# Template register map
Vendor: VendorName Co.Ltd; Series: SeriesName; File version: 1.2
CPU: CM7 r0p1, little endian, MPU, FPU, 4 interrupt priority bits
Registers are 32-bit, read-write, no defined reset value unless marked. A register's access mark holds for its fields unless they carry their own. Offsets are from the block's base; [hi:lo] are bit positions; {n}, {i} and the like mark numbered series; 'fields as' and 'values as' point back to an identical list.

## PMBUS — Power Management Bus
Base 0x40064000
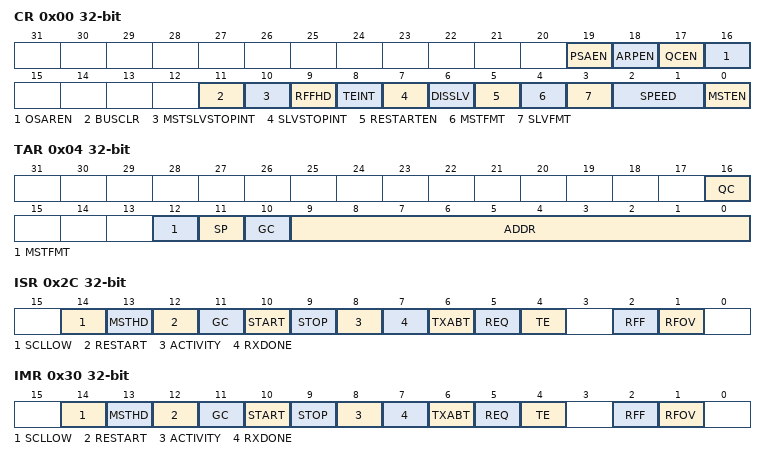
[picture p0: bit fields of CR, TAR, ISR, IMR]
0x00 CR — PMBUS control register
  [19] PSAEN — PMBUS PSAEN bit: enable PMBUS as persistent slave device
  [18] ARPEN — PMBUS ARPEN bit: ARP commands enable
  [17] QCEN — PMBUS QCEN bit: PMBUS slave receives quick commands enable
  [16] OSAREN — PMBUS OSAREN bit: enable the usage of OPT_SAR register
  [11] BUSCLR — PMBUS BUSCLR bit: bus clear is enabled
  [10] MSTSLVSTOPINT — PMBUS MSTSLVSTOPINT bit: master whether active
  [9] RFFHD ro — PMBUS RFFHD bit: PMBUS holds the bus selection
  [8] TEINT — PMBUS TEINT bit: controls whether a TX_EMPTY interrupt is generated
  [7] SLVSTOPINT — PMBUS SLVSTOPINT bit: controls whether a STOP interrupt is generated in the slave mode
  [6] DISSLV — PMBUS DISSLV bit: controls whether PMBUS has its slave disabled
  [5] RESTARTEN — PMBUS RESTARTEN bit: RESTART enable
  [4] MSTFMT ro — PMBUS MSTFMT bit: addressing mode when PMBUS is acting as a master
  [3] SLVFMT — PMBUS SLVFMT bit: controls whether it responds to 7- or 10-bit addresses
  [2:1] SPEED — PMBUS SPEED[1:0] bit: control at which speed the PMBUS operates in the master mode
  [0] MSTEN — PMBUS MSTEN bit: controls whether the PMBUS master is enabled
0x04 TAR — PMBUS target address register
  [16] QC — PMBUS QC bit: whether quick command is to be performed
  [12] MSTFMT — PMBUS MSTFMT bit: address transmit format selection
  [11] SP — PMBUS SP bit: whether software performs a general call or start byte command
  [10] GC — PMBUS GC bit: general call control
  [9:0] ADDR — PMBUS ADDR[9:0] bit: target address for any master transaction
0x08 SAR — PMBUS slave address register
  [9:0] ADDR — PMBUS ADDR[9:0] bit: PMBUS interface slave address
0x14 SSHR — PMBUS standard mode SCL high count register
  [15:0] PMBUS_SSHR — PMBUS PMBUS_SSHR[15:0] bit: set the SCL clock high-period count for standard mode
0x18 SSLR — PMBUS standard mode SCL low count register
  [15:0] PMBUS_SSLR — PMBUS PMBUS_SSLR[15:0] bit: set the SCL clock low-period count for standard mode
0x1C FSHR — PMBUS fast mode/fast mode plus SCL high count register
  [15:0] PMBUS_FSHR — PMBUS PMBUS_FSHR[15:0] bit: set the SCL clock high-period count for fast/fast plus mode
0x20 FSLR — PMBUS fast mode/fast mode plus SCL low count register
  [15:0] PMBUS_FSLR — PMBUS PMBUS_FSLR[15:0] bit: set the SCL clock low-period count for fast/fast plus mode
0x2C ISR ro — PMBUS interrupt status register
  [14] SCLLOW — PMBUS SCLLOW bit: SCL low power timeout detection
  [13] MSTHD — PMBUS MSTHD bit: master hold the bus
  [12] RESTART — PMBUS RESTART bit: restart detection
  [11] GC — PMBUS GC bit: general call
  [10] START — PMBUS START bit: START condition detection
  [9] STOP — PMBUS STOP bit: STOP condition detection
  [8] ACTIVITY — PMBUS ACTIVITY bit: capture PMBUS module activity
  [7] RXDONE — PMBUS RXDONE bit: slave transmit done
  [6] TXABT — PMBUS TXABT bit: transmit abort
  [5] REQ — PMBUS REQ bit: read request
  [4] TE — PMBUS TE bit: transmit buffer empty
  [2] RFF — PMBUS RFF bit: receive buffer full
  [1] RFOV — PMBUS RFOV bit: receive buffer overflow
0x30 IMR — PMBUS interrupt mask register
  [14] SCLLOW — PMBUS SCLLOW bit: SCL_STUCK_LOW interruption shield control
  [13] MSTHD — PMBUS MSTHD bit: MST_ON_HOLD interruption shield control
  [12] RESTART — PMBUS RESTART bit: RESTART interruption shield control
  [11] GC — PMBUS GC bit: GC interruption shield control
  [10] START — PMBUS START bit: START interruption shield control
  [9] STOP — PMBUS STOP bit: STOP interruption shield control
  [8] ACTIVITY — PMBUS ACTIVITY bit: ACTIVITY interruption shield control
  [7] RXDONE — PMBUS RXDONE bit: RX_DONE interruption shield control
  [6] TXABT — PMBUS TXABT bit: TX_ABRT interruption shield control
  [5] REQ — PMBUS REQ bit: RD_REQ interruption shield control
  [4] TE — PMBUS TE bit: TX_EMPTY interruption shield control
  [2] RFF — PMBUS RFF bit: RX_FULL interruption shield control
  [1] RFOV — PMBUS RFOV bit: RX_OVER interruption shield control
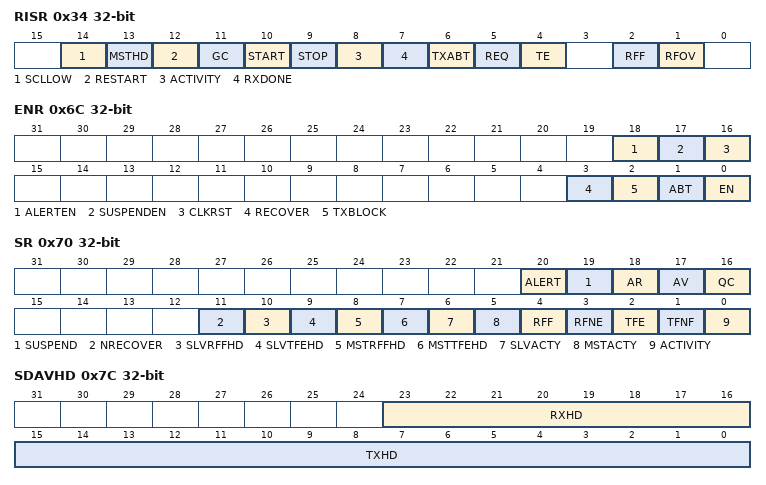
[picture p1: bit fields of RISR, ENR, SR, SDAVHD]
0x34 RISR ro — PMBUS RAW interrupt status register
  fields as ISR
0x38 RFTL — PMBUS receive threshold register
  [3:0] RX_TL — PMBUS RX_TL[3:0] bit: receive FIFO threshold level
0x3C TFTL — PMBUS transmit threshold register
  [3:0] TX_TL — PMBUS TX_TL[3:0] bit: transmit FIFO threshold level
0x40 ICR ro — PMBUS combined and independent interrupt clear register
  [0] ALL — PMBUS ALL bit: clear all combined and independent interrupts
0x48 CLRRXOV ro — PMBUS RX_OVER interrupt clear register
  [0] RFOV — PMBUS RFOV bit: clear the RX_OVER interrupt
0x50 CLRREQ ro — PMBUS RD_REQ interrupt clear register
  [0] RDREQ — PMBUS RDREQ bit: clear the RD_REQ interrupt
0x54 CLRTXABT ro — PMBUS TX_ABRT interrupt clear register
  [0] TXABT — PMBUS TXABT bit: clear the TX_ABRT interrupt
0x58 CLRRXDO ro — PMBUS RX_DONE interrupt clear register
  [0] RXDONE — PMBUS RXDONE bit: clear the RX_DONE interrupt
0x5C CLRACTY ro — PMBUS ACTIVITY interrupt clear register
  [0] ACTIVITY — PMBUS ACTIVITY bit: clears the ACTIVITY interrupt
0x60 CLRSTOP ro — PMBUS STOP_DET interrupt clear register
  [0] STOP — PMBUS STOP bit: clear the STOP interrupt
0x64 CLRSTART ro — PMBUS START_DET interrupt clear register
  [0] START — PMBUS START bit: clear the START interrupt
0x68 CLRGC ro — PMBUS GEN_CALL interrupt clear register
  [0] GC — PMBUS GC bit: clear the GC interrupt
0x6C ENR — PMBUS enable register
  [18] ALERTEN — PMBUS ALERTEN bit: PMBUS alert enable
  [17] SUSPENDEN — PMBUS SUSPENDEN bit: control PMBUS signal enable
  [16] CLKRST — PMBUS CLKRST bit: initiate the PMBUS master clock reset
  [3] RECOVER — PMBUS RECOVER bit: SDA recover mode enable
  [2] TXBLOCK — PMBUS TXBLOCK bit: block data transmit on PMBUS control
  [1] ABT — PMBUS ABT bit: PMBUS transfer abort
  [0] EN — PMBUS EN bit: PMBUS module enable
0x70 SR ro — PMBUS status register
  [20] ALERT — PMBUS ALERT bit: PMBUS alert status bit
  [19] SUSPEND — PMBUS SUSPEND bit: PMBUS stop signal status
  [18] AR — PMBUS AR bit: PMBUS save address resolved status bits
  [17] AV — PMBUS AV bit: PMBUS slave address valid status bit
  [16] QC — PMBUS QC bit: PMBUS quick command status bit
  [11] NRECOVER — PMBUS NRECOVER bit: an SDA stuck at low is not recovered after the recovery mechanism
  [10] SLVRFFHD — PMBUS SLVRFFHD bit: the BUS hold in slave mode due to the Rx FIFO being full
  [9] SLVTFEHD — PMBUS SLVTFEHD bit: the BUS hold in slave mode for the read request when the Tx FIFO is empty
  [8] MSTRFFHD — PMBUS MSTRFFHD bit: the BUS Hold in master mode due to Rx FIFO is Full
  [7] MSTTFEHD — PMBUS MSTTFEHD bit: the BUS hold because of the Tx FIFO being empty
  [6] SLVACTY — PMBUS SLVACTY bit: slave FSM activity status
  [5] MSTACTY — PMBUS MSTACTY bit: master FSM activity status
  [4] RFF — PMBUS RFF bit: receive FIFO completely full
  [3] RFNE — PMBUS RFNE bit: receive FIFO not empty
  [2] TFE — PMBUS TFE bit: transmit FIFO completely empty
  [1] TFNF — PMBUS TFNF bit: transmit FIFO not full
  [0] ACTIVITY — PMBUS ACTIVITY bit: PMBUS activity status
0x74 TFL ro — PMBUS transmit FIFO level register
  [4:0] TX_CNT — PMBUS TX_CNT[4:0] bit: contain the number of valid data entries in the transmit FIFO
0x78 RFL ro — PMBUS receive FIFO level register
  [4:0] RX_CNT — PMBUS RX_CNT[4:0] bit: contain the number of valid data entries in the transmit FIFO
0x7C SDAVHD — PMBUS SDA hold time register
  [23:16] RXHD — PMBUS RXHD[7:0] bit: set the internal SDA hold time
  [15:0] TXHD — PMBUS TXHD[15:0] bit: set the SDA hold time
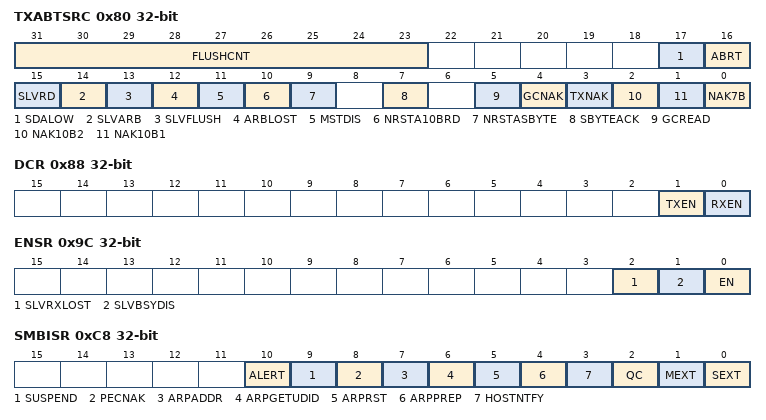
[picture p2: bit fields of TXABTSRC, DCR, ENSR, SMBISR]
0x80 TXABTSRC ro — PMBUS transfer abort source register
  [31:23] FLUSHCNT — PMBUS FLUSHCNT[8:0] bit: number of data/commands in the TX FIFO that were flushed due to transfer interrupt
  [17] SDALOW — PMBUS SDALOW bit: this bit is set when SDA low timeout is detected by the master device
  [16] ABRT — PMBUS ABRT bit: set when transfer abort is detected by the master device
  [15] SLVRD — PMBUS SLVRD bit: this bit is set when PMBUS is requested for data from send mode to write 1 to PMBUS_DR.CMD
  [14] SLVARB — PMBUS SLVARB bit: this bit and bit 12 are set simultaneously if the bus is lost when the slave device sends data
  [13] SLVFLUSH — PMBUS SLVFLUSH bit: clear TX FIFO old data
  [12] ARBLOST — PMBUS ARBLOST bit: this bit is set if the master device arbitration fails
  [11] MSTDIS — PMBUS MSTDIS bit: this bit is set when the master device is operated in the disabled master mode
  [10] NRSTA10BRD — PMBUS NRSTA10BRD bit: the master device sends a read request in 10-bit addressing mode
  [9] NRSTASBYTE — PMBUS NRSTASBYTE bit: send the start byte when RESTART is not enabled
  [7] SBYTEACK — PMBUS SBYTEACK bit: set when the master device sends the start byte and is responded
  [5] GCREAD — PMBUS GCREAD bit: set when the master device sends a general call
  [4] GCNAK — PMBUS GCNAK bit: set when no slave device responds after a general call is sent by the master device
  [3] TXNAK — PMBUS TXNAK bit: no slave device responds to the data sent
  [2] NAK10B2 — PMBUS NAK10B2 bit: the master device operates in 10-bit addressing mode
  [1] NAK10B1 — PMBUS NAK10B1 bit: the master device operates in 10-bit addressing mode
  [0] NAK7B — PMBUS NAK7B bit: the master device operates in 7-bit addressing mode
0x84 SLVNAK — PMBUS slave receive NACK register
  [0] NACK — PMBUS NACK bit: generate NACK control
0x88 DCR — PMBUS DMA control register
  [1] TXEN — PMBUS TXEN bit: transmit DMA enable
  [0] RXEN — PMBUS RXEN bit: receive DMA enable
0x8C DTTL — PMBUS DMA transmit waterline register
  [3:0] DMATDL — PMBUS DMATDL[3:0] bit: DMA transmit data level
0x90 DRTL — PMBUS DMA receive waterline register
  [3:0] DMARDL — PMBUS DMARDL[3:0] bit: DMA receive data level
0x94 SDASETUP — PMBUS SDA setup time register
  [7:0] SDASETUP — PMBUS SDASETUP[7:0] bit: SDA set up time
0x98 GCACK — PMBUS general call ACK register
  [0] GC — PMBUS GC bit: ACK general call
0x9C ENSR ro — PMBUS ENABLE status register
  [2] SLVRXLOST — PMBUS SLVRXLOST bit: slave receive lost
  [1] SLVBSYDIS — PMBUS SLVBSYDIS bit: when slave receive disable
  [0] EN — PMBUS EN bit: PMBUS start status
0xA0 FLTLEN — PMBUS filter register
  [7:0] FLTLEN — PMBUS FLTLEN[7:0] bit: configure the spike suppression time
0xA8 CLRRESTART ro — PMBUS clear RESTART interrupt register
  [0] CLRRESTART — PMBUS CLRRESTART bit: clear RESTART interrupt
0xAC SCLLTMO — PMBUS SCL low timeout register
  [31:0] TIMEOUT — PMBUS TIMEOUT[31:0] bit: configure the duration of SCL low timeout
0xB0 SDALTMO — PMBUS SDA low timeout register
  [31:0] TIMEOUT — PMBUS TIMEOUT[31:0] bit: configure the duration of SDA low timeout
0xB4 CLRSCLL ro — PMBUS clear SCL_STUCK interrupt register
  [0] SCLLOW — PMBUS SCLLOW bit: clear SCL_STUCK interrupt
0xBC SEXT — PMBUS SMBUS slave device clock extension timeout register
  [31:0] SEXT — PMBUS SEXT[31:0] bit: configure the slave device clock extension timeout
0xC0 MEXT — PMBUS SMBUS master device clock extension timeout register
  [31:0] MEXT — PMBUS MEXT[31:0] bit: configure the clock extension timeout
0xC4 IDLECNT — PMBUS SMBUS bus idle count register
  [15:0] IDLECNT — PMBUS IDLECNT[15:0] bit: configure the required bus idle time
0xC8 SMBISR ro — PMBUS SMBUS interrupt status register
  [10] ALERT — PMBUS ALERT bit: set when the slave device alarm is detected
  [9] SUSPEND — PMBUS SUSPEND bit: SMBUS stop mode select
  [8] PECNAK — PMBUS PECNAK bit: set when the slave device does not respond to the PEC byte of the ARP command
  [7] ARPADDR — PMBUS ARPADDR bit: set when the assign address ARP command is received
  [6] ARPGETUDID — PMBUS ARPGETUDID bit: set when the get UDID ARP command is received
  [5] ARPRST — PMBUS ARPRST bit: set when the reset ARP command is received
  [4] ARPPREP — PMBUS ARPPREP bit: set when the prepare to ARP command is received
  [3] HOSTNTFY — PMBUS HOSTNTFY bit: set when the host notify command is received
  [2] QC — PMBUS QC bit: set when the quick command is received
  [1] MEXT — PMBUS MEXT bit: set when the master device transmits the clock extension timeout of a byte
  [0] SEXT — PMBUS SEXT bit: set when the clock for the slave device to communicate for one time extends timeout
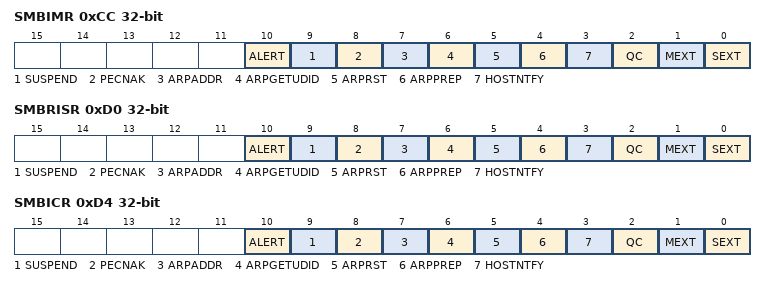
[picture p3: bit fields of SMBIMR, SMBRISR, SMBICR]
0xCC SMBIMR — PMBUS SMBUS interrupt mask register
  [10] ALERT — PMBUS ALERT bit: SMB_ALT interrupt shield control
  [9] SUSPEND — PMBUS SUSPEND bit: SMB_SPD interrupt shield control
  [8] PECNAK — PMBUS PECNAK bit: PEC_NACK interrupt shield control
  [7] ARPADDR — PMBUS ARPADDR bit: ARP_ASSGN interrupt shield control
  [6] ARPGETUDID — PMBUS ARPGETUDID bit: ARP_UDID interrupt shield control
  [5] ARPRST — PMBUS ARPRST bit: ARP_RST interrupt shield control
  [4] ARPPREP — PMBUS ARPPREP bit: ARP_PRE interrupt shield control
  [3] HOSTNTFY — PMBUS HOSTNTFY bit: ARP_NOTIFY interrupt shield control
  [2] QC — PMBUS QC bit: ARP_QUICK interrupt shield control
  [1] MEXT — PMBUS MEXT bit: MST_TMO interrupt shield control
  [0] SEXT — PMBUS SEXT bit: SLV_TMO interrupt shield control
0xD0 SMBRISR ro — PMBUS SMBUS RAW interrupt register
  fields as SMBISR
0xD4 SMBICR wo — PMBUS SMBUS combinational and independent interrupt clear register
  [10] ALERT — PMBUS ALERT bit: clear SMB_ALT interrupt
  [9] SUSPEND — PMBUS SUSPEND bit: clear SMB_SPD interrupt
  [8] PECNAK — PMBUS PECNAK bit: clear PEC_NACK interrupt
  [7] ARPADDR — PMBUS ARPADDR bit: clear ARP_ASSGN interrupt
  [6] ARPGETUDID — PMBUS ARPGETUDID bit: clear ARP_UDID interrupt
  [5] ARPRST — PMBUS ARPRST bit: clear ARP_RST interrupt
  [4] ARPPREP — PMBUS ARPPREP bit: clear ARP_PRE interrupt
  [3] HOSTNTFY — PMBUS HOSTNTFY bit: clear ARP_NOTIFY interrupt
  [2] QC — PMBUS QC bit: clear ARP_QUICK interrupt
  [1] MEXT — PMBUS MEXT bit: clear MST_TMO interrupt
  [0] SEXT — PMBUS SEXT bit: clear SLV_TMO interrupt
0xD8 OSAR — PMBUS optional slave address register
  [6:0] OSAR — PMBUS OSAR[6:0] bit: the slave address of the SMBUS interface when working in SMBUS slave mode
{0xDC+4i} UDID{i} (i=0..3) — PMBUS SMBus UDID MSB register {i}
  [31:0] UDID{i} — PMBUS UDID{i}[31:0] bit: configure SMBUS UDID{i}
